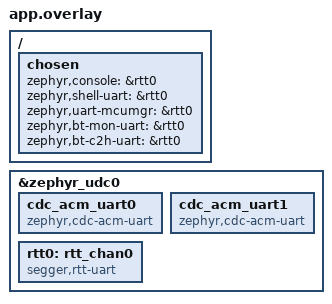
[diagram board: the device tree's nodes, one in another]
/*
 * Copyright (c) 2023 Nordic Semiconductor ASA
 *
 * SPDX-License-Identifier: LicenseRef-Nordic-5-Clause
 */

&zephyr_udc0 {
	cdc_acm_uart0: cdc_acm_uart0 {
		compatible = "zephyr,cdc-acm-uart";
	};

	cdc_acm_uart1: cdc_acm_uart1 {
		compatible = "zephyr,cdc-acm-uart";
	};

	rtt0: rtt_chan0 {
		compatible = "segger,rtt-uart";
		status = "okay";
	};
};

/ {
	chosen {
		zephyr,console = &rtt0;
		zephyr,shell-uart = &rtt0;
		zephyr,uart-mcumgr = &rtt0;
		zephyr,bt-mon-uart = &rtt0;
		zephyr,bt-c2h-uart = &rtt0;
	};
};
